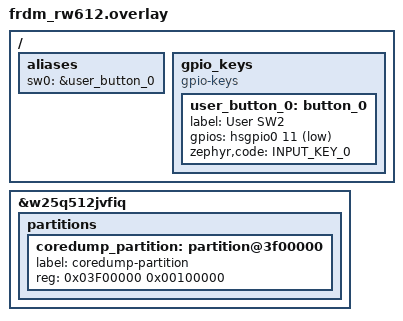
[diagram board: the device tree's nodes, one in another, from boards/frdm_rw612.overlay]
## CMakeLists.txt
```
# SPDX-License-Identifier: Apache-2.0

cmake_minimum_required(VERSION 3.20.0)

# TODO document in readme
if (EXISTS "${CMAKE_CURRENT_SOURCE_DIR}/credentials.conf")
    list(APPEND EXTRA_CONF_FILE "${CMAKE_CURRENT_SOURCE_DIR}/credentials.conf")
endif()


find_package(Zephyr REQUIRED HINTS $ENV{ZEPHYR_BASE})
project(wifi-core-dumps)

target_sources(app PRIVATE
        src/main.c
        src/wifi.c
)
```

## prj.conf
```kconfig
CONFIG_SPOTFLOW=y

#logging
CONFIG_PRINTK=y
CONFIG_LOG=y

# net
CONFIG_NETWORKING=y
CONFIG_NET_MGMT=y
CONFIG_NET_MGMT_EVENT=y
CONFIG_NET_MGMT_EVENT_INFO=y
CONFIG_NET_CONFIG_AUTO_INIT=n
CONFIG_NET_CONNECTION_MANAGER=y
CONFIG_NET_DHCPV4=y
CONFIG_NET_IPV4=y
CONFIG_NET_IPV6=n
CONFIG_NET_TCP=y
CONFIG_NET_UDP=y

# WIFI
CONFIG_WIFI=y
CONFIG_WIFI_NM=y
CONFIG_NET_L2_WIFI_MGMT=y

CONFIG_SPOTFLOW_PROCESSING_BACKEND_LOG_LEVEL=4

CONFIG_DEBUG_COREDUMP=y
CONFIG_DEBUG_COREDUMP_BACKEND_LOGGING=y
```

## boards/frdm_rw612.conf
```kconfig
CONFIG_WIFI_NXP=y
CONFIG_NXP_RW610=y
CONFIG_ETH_DRIVER=n
CONFIG_NET_BUF_DATA_SIZE=1744

CONFIG_NXP_WIFI_SOFTAP_SUPPORT=n
```

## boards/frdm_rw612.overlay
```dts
/*GPIO not available in 4.1.0, adding based on commit
https://github.com/zephyrproject-rtos/zephyr/commit/2df6b7fd2dea95105b3598c41fecbd7089fab080*/
#include <zephyr/dt-bindings/input/input-event-codes.h>
/ {
	aliases {
		/* make an alias so we can refer to “sw0” in code */
		sw0 = &user_button_0;
	};

	gpio_keys {
		compatible = "gpio-keys";
		user_button_0: button_0 {
			label = "User SW2";
			gpios = <&hsgpio0 11 (GPIO_ACTIVE_LOW | GPIO_PULL_UP)>;
			zephyr,code = <INPUT_KEY_0>;
			status = "okay";
		};
	};
};

/* external flash chip - winbond - to more information
	  zephyr\boards\nxp\frdm_rw612\frdm_rw612_common.dtsi*/
&w25q512jvfiq {
	partitions {
		coredump_partition: partition@3f00000 {
			label = "coredump-partition";
			reg   = <0x03F00000 0x00100000>; /* last 1MiB of 64 MiB flash */
		};
	};
};
```

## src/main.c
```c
#include <zephyr/kernel.h>
#include <zephyr/logging/log.h>

#include "wifi.h"
#include "zephyr/debug/coredump.h"

#include "zephyr/drivers/gpio.h"
#include <zephyr/device.h>

#include <zephyr/sys/reboot.h>
#include <zephyr/fatal.h>   /* for k_sys_fatal_error_handler */
#include <zephyr/logging/log_ctrl.h>


LOG_MODULE_REGISTER(MAIN, LOG_LEVEL_INF);

#define SW0_NODE	DT_ALIAS(sw0)
#if !DT_NODE_HAS_STATUS_OKAY(SW0_NODE)
#error "Unsupported board: sw2 devicetree alias is not defined"
#endif
static const struct gpio_dt_spec button = GPIO_DT_SPEC_GET_OR(SW0_NODE, gpios,
							      {0});
static struct gpio_callback button_cb_data;
static int prepare_button();
void check_coredump();


int main(void)
{
	LOG_INF("Starting Spotflow logging example");
	int ret;
	ret = prepare_button();
	if (ret != 0) {
		LOG_ERR("Failed to prepare button, exiting");
		return ret;
	}

	// Wait for the initialization of Wi-Fi device
	k_sleep(K_SECONDS(1));

	init_wifi();
	connect_to_wifi();
	for (int i = 0; i < 20; i++) {
		LOG_INF("Hello from Zephyr to Spotflow: %d", i);
		k_sleep(K_SECONDS(2));
	}

	return 0;
}


void button_pressed(const struct device *dev, struct gpio_callback *cb,
		    uint32_t pins)
{
	LOG_INF("Button pressed. Going to oops in 2 seconds.");
	k_sleep(K_SECONDS(2));
	k_panic();
}


static int prepare_button()
{
	int ret;
	if (!gpio_is_ready_dt(&button)) {
		LOG_ERR("Error: button device %s is not ready",
		       button.port->name);
		return -EINVAL;
	}

	ret = gpio_pin_configure_dt(&button, GPIO_INPUT);
	if (ret != 0) {
		LOG_ERR("Error %d: failed to configure %s pin %d",
		       ret, button.port->name, button.pin);
		return ret;
	}

	ret = gpio_pin_interrupt_configure_dt(&button,
					      GPIO_INT_EDGE_TO_ACTIVE);
	if (ret != 0) {
		LOG_ERR("Error %d: failed to configure interrupt on %s pin %d",
			ret, button.port->name, button.pin);
		return ret;
	}

	gpio_init_callback(&button_cb_data, button_pressed, BIT(button.pin));
	gpio_add_callback(button.port, &button_cb_data);

	LOG_DBG("Set up button at %s pin %d", button.port->name, button.pin);
	return 0;

}

/*to reboot device after panic*/
FUNC_NORETURN void k_sys_fatal_error_handler(unsigned int reason,
				      const struct arch_esf *esf)
{
	ARG_UNUSED(esf);

	LOG_PANIC();
	LOG_ERR("Halting system");
	k_sleep(K_SECONDS(10));
	sys_reboot(SYS_REBOOT_COLD);
	CODE_UNREACHABLE;
}
```

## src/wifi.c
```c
#include <zephyr/kernel.h>
#include <zephyr/logging/log.h>
#include <zephyr/net/wifi_mgmt.h>
#include <zephyr/net/dhcpv4_server.h>

LOG_MODULE_REGISTER(spotflow_sample_wifi, LOG_LEVEL_INF);

#define MACSTR "%02X:%02X:%02X:%02X:%02X:%02X"

#define NET_EVENT_WIFI_MASK                                                   \
	(NET_EVENT_WIFI_CONNECT_RESULT | NET_EVENT_WIFI_DISCONNECT_RESULT |   \
	 NET_EVENT_WIFI_AP_ENABLE_RESULT | NET_EVENT_WIFI_AP_DISABLE_RESULT | \
	 NET_EVENT_WIFI_AP_STA_CONNECTED | NET_EVENT_WIFI_AP_STA_DISCONNECTED)

#define WIFI_SSID CONFIG_NET_WIFI_SSID
#define WIFI_PSK CONFIG_NET_WIFI_PASSWORD

static struct net_if* sta_iface;

static struct wifi_connect_req_params sta_config;

static struct net_mgmt_event_callback cb;

static void wifi_event_handler(struct net_mgmt_event_callback* cb, uint32_t mgmt_event,
			       struct net_if* iface)
{
	switch (mgmt_event) {
	case NET_EVENT_WIFI_CONNECT_RESULT: {
		struct wifi_status* result = (struct wifi_status*)cb->info;

		if (result->status == 0) {
			LOG_INF("Connected to %s", WIFI_SSID);
		} else {
			LOG_ERR("Failed to connect to %s (status %d)", WIFI_SSID, result->status);
		}
		break;
	}
	case NET_EVENT_WIFI_DISCONNECT_RESULT: {
		struct wifi_status* result = (struct wifi_status*)cb->info;

		if (result->status == 0) {
			LOG_INF("Disconnected from %s", WIFI_SSID);
		} else {
			LOG_ERR("Unexpected disconnect from %s (reason %d)", WIFI_SSID,
				result->status);
		}
		break;
	}
	case NET_EVENT_WIFI_AP_ENABLE_RESULT: {
		LOG_INF("AP Mode is enabled. Waiting for station to connect");
		break;
	}
	case NET_EVENT_WIFI_AP_DISABLE_RESULT: {
		LOG_INF("AP Mode is disabled.");
		break;
	}
	case NET_EVENT_WIFI_AP_STA_CONNECTED: {
		struct wifi_ap_sta_info* sta_info = (struct wifi_ap_sta_info*)cb->info;

		LOG_INF("station: " MACSTR " joined ", sta_info->mac[0], sta_info->mac[1],
			sta_info->mac[2], sta_info->mac[3], sta_info->mac[4], sta_info->mac[5]);
		break;
	}
	case NET_EVENT_WIFI_AP_STA_DISCONNECTED: {
		struct wifi_ap_sta_info* sta_info = (struct wifi_ap_sta_info*)cb->info;

		LOG_INF("station: " MACSTR " leave ", sta_info->mac[0], sta_info->mac[1],
			sta_info->mac[2], sta_info->mac[3], sta_info->mac[4], sta_info->mac[5]);
		break;
	}
	default:
		break;
	}
}

int connect_to_wifi(void)
{
	if (!sta_iface) {
		LOG_ERR("STA: interface not initialized");
		return -EIO;
	}

	sta_config.ssid = (const uint8_t*)WIFI_SSID;
	sta_config.ssid_length = strlen(WIFI_SSID);
	sta_config.psk = (const uint8_t*)WIFI_PSK;
	sta_config.psk_length = strlen(WIFI_PSK);
	sta_config.security = WIFI_SECURITY_TYPE_PSK;
	sta_config.channel = WIFI_CHANNEL_ANY;
	sta_config.band = WIFI_FREQ_BAND_2_4_GHZ;

	LOG_INF("Connecting to SSID: %s\n", sta_config.ssid);

	int ret = net_mgmt(NET_REQUEST_WIFI_CONNECT, sta_iface, &sta_config,
			   sizeof(struct wifi_connect_req_params));
	if (ret) {
		LOG_ERR("Unable to Connect to (%s)", WIFI_SSID);
	}

	return ret;
}

int init_wifi(void)
{
	net_mgmt_init_event_callback(&cb, wifi_event_handler, NET_EVENT_WIFI_MASK);
	net_mgmt_add_event_callback(&cb);

	/* Get STA interface in AP-STA mode. */
	sta_iface = net_if_get_wifi_sta();

	return 0;
}
```
